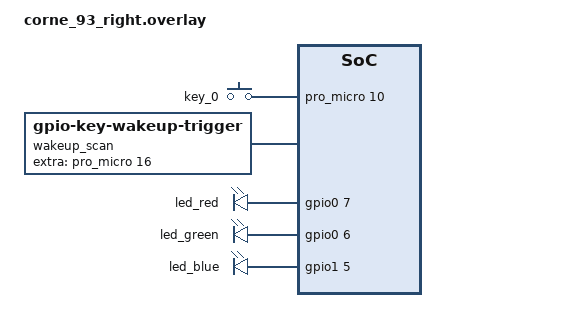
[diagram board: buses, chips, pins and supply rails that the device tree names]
#include "corne_93.dtsi"

&kscan {
    row-gpios
        = <&pro_micro 19 (GPIO_ACTIVE_HIGH | GPIO_PULL_DOWN)>
        , <&pro_micro 10 (GPIO_ACTIVE_HIGH | GPIO_PULL_DOWN)>
        , <&pro_micro 8 (GPIO_ACTIVE_HIGH | GPIO_PULL_DOWN)>
        , <&pro_micro 9 (GPIO_ACTIVE_HIGH | GPIO_PULL_DOWN)>
        ;

    col-gpios
        = <&pro_micro 21 GPIO_ACTIVE_HIGH>
        , <&pro_micro 16 GPIO_ACTIVE_HIGH>
        , <&pro_micro 14 GPIO_ACTIVE_HIGH>
        , <&pro_micro 15 GPIO_ACTIVE_HIGH>
        , <&pro_micro 20 GPIO_ACTIVE_HIGH>
        , <&pro_micro 18 GPIO_ACTIVE_HIGH>
        ;
};
&default_transform {
    col-offset = <6>;
};
/ {
    soft_off_gpio_key: soft_off_gpio_key {
        compatible = "gpio-keys";
				key_0: key_0 {
					gpios = <&pro_micro 10 (GPIO_ACTIVE_HIGH | GPIO_PULL_DOWN)>;
				};
    };

    wakeup_scan: wakeup_scan {
        compatible = "zmk,gpio-key-wakeup-trigger";
		  	trigger = <&key_0>;
        wakeup-source;
        extra-gpios = <&pro_micro 16 GPIO_ACTIVE_HIGH>;
    };

    soft_off_wakers {
        compatible = "zmk,soft-off-wakeup-sources";
        wakeup-sources = <&kscan>, <&wakeup_scan>;
    };
    leds {
        compatible = "gpio-leds";
				status = "okay";
        led_red: led_red {
            gpios = <&gpio0 7 GPIO_ACTIVE_HIGH>;
        };
        led_green: led_green {
            gpios = <&gpio0 6 GPIO_ACTIVE_HIGH>;
        };
        led_blue: led_blue {
            gpios = <&gpio1 5 GPIO_ACTIVE_HIGH>;
        };
    };
    aliases {
        led-red = &led_red;
        led-green = &led_green;
        led-blue = &led_blue;
        led_red = &led_red;
        led_green = &led_green;
        led_blue = &led_blue;
    };
};
